# STM32G563 register map
File version: 2.0.0
CPU: CM33 r0p4, little endian, MPU, FPU, 4 interrupt priority bits
Registers are 32-bit, read-write, reset 0x0 unless marked. A register's access mark holds for its fields unless they carry their own. Offsets are from the block's base; [hi:lo] are bit positions; {n}, {i} and the like mark numbered series; 'fields as' and 'values as' point back to an identical list.

## TIM16 — TIM16 address block description
Base 0x40014400
Same registers: TIM16_S 0x50014400
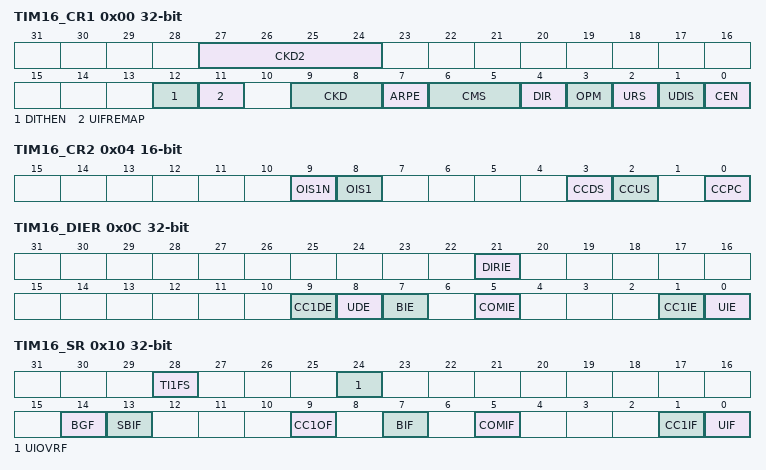
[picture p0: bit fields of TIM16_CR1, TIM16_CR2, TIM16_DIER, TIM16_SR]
0x00 TIM16_CR1 — TIM16 control register 1
  [27:24] CKD2 — Clock division 2
    0=No Division; 1=tless thansub>DTS2less than/sub> = 4*tless thansub>DTSless than/sub>; 2=tless thansub>DTS2less than/sub> = 16*tless thansub>DTSless than/sub>; 3=tless thansub>DTS2less than/sub> = 64*tless thansub>DTSless than/sub>; 4=tless thansub>DTS2less than/sub> = 256*tless thansub>DTSless than/sub>; 5=tless thansub>DTS2less than/sub> = 1024*tless thansub>DTSless than/sub>; 6=tless thansub>DTS2less than/sub> = 4096*tless thansub>DTSless than/sub>; 7=tless thansub>DTS2less than/sub> = 16384*tless thansub>DTSless than/sub>; 8=tless thansub>DTS2less than/sub> = 65536*tless thansub>DTSless than/sub>; 9=tless thansub>DTS2less than/sub> = 262144*tless thansub>DTSless than/sub>
  [12] DITHEN — Dithering enable
    0=Dithering disabled; 1=Dithering enabled
  [11] UIFREMAP — UIF status bit remapping
    0=No remapping. UIF status bit is not copied to TIMx_CNT register bit 31.; 1=Remapping enabled. UIF status bit is copied to TIMx_CNT register bit 31.
  [9:8] CKD — Clock division
    0=tless thansub>DTSless than/sub> = tless thansub>tim_ker_ckless than/sub>; 1=tless thansub>DTSless than/sub> = 2*tless thansub>tim_ker_ckless than/sub>; 2=tless thansub>DTSless than/sub> = 4*tless thansub>tim_ker_ckless than/sub>; 3=tless thansub>DTSless than/sub> = 8*tless thansub>tim_ker_ckless than/sub>
  [7] ARPE — Auto-reload preload enable
    0=TIMx_ARR register is not buffered; 1=TIMx_ARR register is buffered
  [6:5] CMS — Center-aligned mode selection
    0=Edge-aligned mode. The counter counts up or down depending on the direction bit (DIR).; 1=Center-aligned mode 1. The counter counts up and down alternatively. Output compare interrupt flags of channels configured in output (CCxS = 00 in TIMx_CCMRx register) are set only when the counter is counting down.; 2=Center-aligned mode 2. The counter counts up and down alternatively. Output compare interrupt flags of channels configured in output (CCxS = 00 in TIMx_CCMRx register) are set only when the counter is counting up.; 3=Center-aligned mode 3. The counter counts up and down alternatively. Output compare interrupt flags of channels configured in output (CCxS = 00 in TIMx_CCMRx register) are set both when the counter is counting up or down.
  [4] DIR — Direction
    0=Counter used as upcounter; 1=Counter used as downcounter
  [3] OPM — One pulse mode
    0=Counter is not stopped at update event; 1=Counter stops counting at the next update event (clearing the bit CEN)
  [2] URS — Update request source
    0=Any of the following events generate an update interrupt or DMA request if enabled. These events can be:; 1=nly counter overflow/underflow generates an update interrupt or DMA request if enabled
  [1] UDIS — Update disable
    0=UEV enabled. The Update (UEV) event is generated by one of the following events:; 1=UEV disabled. The Update event is not generated, shadow registers keep their value (ARR, PSC, CCRx). However the counter and the prescaler are reinitialized if the UG bit is set or if a hardware reset is received from the slave mode controller.
  [0] CEN — Counter enable
    0=Counter disabled; 1=Counter enabled
0x04 TIM16_CR2 16-bit — TIM16 control register 2
  [9] OIS1N — Output Idle state 1 (tim_oc1n output)
    0=tim_oc1n = 0 after a dead-time when MOE = 0; 1=tim_oc1n = 1 after a dead-time when MOE = 0
  [8] OIS1 — Output Idle state 1 (tim_oc1 output)
    0=tim_oc1 = 0 after a dead-time when MOE = 0; 1=tim_oc1 = 1 after a dead-time when MOE = 0
  [3] CCDS — Capture/compare DMA selection
    0=CCx DMA request sent when CCx event occurs; 1=CCx DMA requests sent when update event occurs
  [2] CCUS — Capture/compare control update selection
    0=When capture/compare control bits are preloaded (CCPC = 1), they are updated by setting the COMG bit only; 1=When capture/compare control bits are preloaded (CCPC = 1), they are updated by setting the COMG bit or when a rising edge occurs on tim_trgi (if available)
  [0] CCPC — Capture/compare preloaded control
    0=CCxE, CCxNE and OCxM bits are not preloaded; 1=CCxE, CCxNE and OCxM bits are preloaded, after having been written, they are updated only when COM bit is set
0x0C TIM16_DIER — TIM16 DMA/interrupt enable register
  [21] DIRIE — Direction change interrupt enable
    0=Direction change interrupt disabled; 1=Direction change interrupt enabled
  [9] CC1DE — Capture/Compare 1 DMA request enable
    0=CC1 DMA request disabled; 1=CC1 DMA request enabled
  [8] UDE — Update DMA request enable
    0=Update DMA request disabled; 1=Update DMA request enabled
  [7] BIE — Break interrupt enable
    0=Break interrupt disabled; 1=Break interrupt enabled
  [5] COMIE — COM interrupt enable
    0=COM interrupt disabled; 1=COM interrupt enabled
  [1] CC1IE — Capture/Compare 1 interrupt enable
    0=CC1 interrupt disabled; 1=CC1 interrupt enabled
  [0] UIE — Update interrupt enable
    0=Update interrupt disabled; 1=Update interrupt enabled
0x10 TIM16_SR — TIM16 status register
  [28] TI1FS ro — tim_ti1f status
    0=tim_ti1f signal is low; 1=tim_ti1f signal is high
  [24] UIOVRF — Update Interrupt Overrun flag
    0=No Update Interrupt Overrun; 1=Update Interrupt Overrun
  [14] BGF — Break generation flag
    0=No break event occurred; 1=A break event was forced with the BG bit
  [13] SBIF — System break interrupt flag
    0=No break event occurred; 1=An active level has been detected on the system break input. An interrupt is generated if BIE = 1 in the TIMx_DIER register.
  [9] CC1OF — Capture/Compare 1 overcapture flag
    0=No overcapture has been detected; 1=The counter value has been captured in TIMx_CCR1 register while CC1IF flag was already set
  [7] BIF — Break interrupt flag
    0=No break event occurred; 1=An active level has been detected on the break input
  [5] COMIF — COM interrupt flag
    0=No COM event occurred; 1=COM interrupt pending
  [1] CC1IF — Capture/Compare 1 interrupt flag
    0=No compare match / No input capture occurred; 1=A compare match or an input capture occurred
  [0] UIF — Update interrupt flag
    0=No update occurred; 1=Update interrupt pending. This bit is set by hardware when the registers are updated:
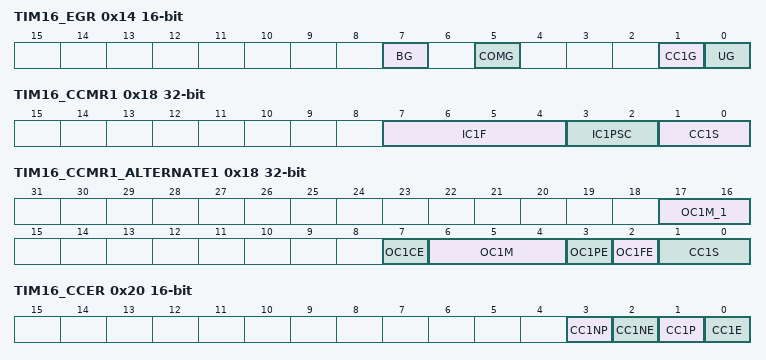
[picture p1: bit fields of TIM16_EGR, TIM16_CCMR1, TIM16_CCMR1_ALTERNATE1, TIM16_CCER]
0x14 TIM16_EGR 16-bit wo — TIM16 event generation register
  [7] BG — Break generation
    0=No action; 1=A break event is generated. MOE bit is cleared and BIF flag is set. Related interrupt or DMA transfer can occur if enabled.
  [5] COMG — Capture/Compare control update generation
    0=No action; 1=When the CCPC bit is set, it is possible to update the CCxE, CCxNE and OCxM bits
  [1] CC1G — Capture/Compare 1 generation
    0=No action; 1=A capture/compare event is generated on channel 1:
  [0] UG — Update generation
    0=No action; 1=Reinitialize the counter and generates an update of the registers. Note that the prescaler counter is cleared too (anyway the prescaler ratio is not affected).
0x18 TIM16_CCMR1 — TIM16 capture/compare mode register 1
  [7:4] IC1F — Input capture 1 filter
    0=No filter, sampling is done at fless thansub>DTSless than/sub>; 1=fless thansub>SAMPLINGless than/sub> = fless thansub>tim_ker_ckless than/sub>, N = 2; 2=fless thansub>SAMPLINGless than/sub> = fless thansub>tim_ker_ckless than/sub>, N = 4; 3=fless thansub>SAMPLINGless than/sub> = fless thansub>tim_ker_ckless than/sub>, N = 8; 4=fless thansub>SAMPLINGless than/sub> = fless thansub>DTSless than/sub>/2, N =; 5=fless thansub>SAMPLINGless than/sub> = fless thansub>DTSless than/sub>/2, N = 8; 6=fless thansub>SAMPLINGless than/sub> = fless thansub>DTSless than/sub>/4, N = 6; 7=fless thansub>SAMPLINGless than/sub> = fless thansub>DTSless than/sub>/4, N = 8; 8=fless thansub>SAMPLINGless than/sub> = fless thansub>DTSless than/sub>/8, N = 6; 9=fless thansub>SAMPLINGless than/sub> = fless thansub>DTSless than/sub>/8, N = 8; 10=fless thansub>SAMPLINGless than/sub> = fless thansub>DTSless than/sub>/16, N = 5; 11=fless thansub>SAMPLINGless than/sub> = fless thansub>DTSless than/sub>/16, N = 6; 12=fless thansub>SAMPLINGless than/sub> = fless thansub>DTSless than/sub>/16, N = 8; 13=fless thansub>SAMPLINGless than/sub> = fless thansub>DTSless than/sub>/32, N = 5; 14=fless thansub>SAMPLINGless than/sub> = fless thansub>DTSless than/sub>/32, N = 6; 15=fless thansub>SAMPLINGless than/sub> = fless thansub>DTSless than/sub>/32, N = 8
  [3:2] IC1PSC — Input capture 1 prescaler
    0=no prescaler, capture is done each time an edge is detected on the capture input; 1=capture is done once every 2 events; 2=capture is done once every 4 events; 3=capture is done once every 8 events
  [1:0] CC1S — Capture/Compare 1 selection
    0=CC1 channel is configured as output; 1=CC1 channel is configured as input, tim_ic1 is mapped on tim_ti1
0x18 TIM16_CCMR1_ALTERNATE1 (alternate view of TIM16_CCMR1) — TIM16 capture/compare mode register 1
  [17:16] OC1M_1 — OC1M[4:3]
  [7] OC1CE — Output Compare 1 clear enable
    0=tim_oc1ref is not affected by the tim_ocref_clr input; 1=tim_oc1ref is cleared as soon as a High level is detected on tim_ocref_clr input
  [6:4] OC1M — OC1M[2:0]: Output Compare 1 mode
    0=Frozen - The comparison between the output compare register TIMx_CCR1 and the counter TIMx_CNT has no effect on the outputs. This mode can be used when the timer serves as a software timebase. When the frozen mode is enabled during timer operation, the output keeps the state (active or inactive) it had before entering the frozen state.; 1=Set channel 1 to active level on match. tim_oc1ref signal is forced high when the counter TIMx_CNT matches the capture/compare register 1 (TIMx_CCR1).; 2=Set channel 1 to inactive level on match. tim_oc1ref signal is forced low when the counter TIMx_CNT matches the capture/compare register 1 (TIMx_CCR1).; 3=Toggle - tim_oc1ref toggles when TIMx_CNT = TIMx_CCR1; 4=Force inactive level - tim_oc1ref is forced low; 5=Force active level - tim_oc1ref is forced high; 6=PWM mode 1 - Channel 1 is active as long as TIMx_CNTless thanTIMx_CCR1 else inactive; 7=PWM mode 2 - Channel 1 is inactive as long as TIMx_CNTless thanTIMx_CCR1 else active
  [3] OC1PE — Output Compare 1 preload enable
    0=Preload register on TIMx_CCR1 disabled. TIMx_CCR1 can be written at anytime, the new value is taken in account immediately.; 1=Preload register on TIMx_CCR1 enabled. Read/Write operations access the preload register. TIMx_CCR1 preload value is loaded in the active register at each update event.
  [2] OC1FE — Output Compare 1 fast enable
    0=CC1 behaves normally depending on counter and CCR1 values even when the trigger is ON. The minimum delay to activate CC1 output when an edge occurs on the trigger input is 5 clock cycles.; 1=An active edge on the trigger input acts like a compare match on CC1 output. Then, tim_ocx is set to the compare level independently of the result of the comparison. Delay to sample the trigger input and to activate CC1 output is reduced to 3 clock cycles. OC1FE acts only if the channel is configured in PWM1 or PWM2 mode.
  [1:0] CC1S — Capture/Compare 1 selection
    values as TIM16_CCMR1.CC1S
0x20 TIM16_CCER 16-bit — TIM16 capture/compare enable register
  [3] CC1NP — Capture/Compare 1 complementary output polarity
    0=tim_oc1n active high; 1=tim_oc1n active low
  [2] CC1NE — Capture/Compare 1 complementary output enable
    0=Off - tim_oc1n is not active. tim_oc1n level is then function of MOE, OSSI, OSSR, OIS1, OIS1N and CC1E bits.; 1=On - tim_oc1n signal is output on the corresponding output pin depending on MOE, OSSI, OSSR, OIS1, OIS1N and CC1E bits
  [1] CC1P — Capture/Compare 1 output polarity
    0=OC1 active high (output mode) / Edge sensitivity selection (input mode, see below); 1=OC1 active low (output mode) / Edge sensitivity selection (input mode, see below)
  [0] CC1E — Capture/Compare 1 output enable
    0=Capture mode disabled / OC1 is not active (see below); 1=Capture mode enabled / OC1 signal is output on the corresponding output pin
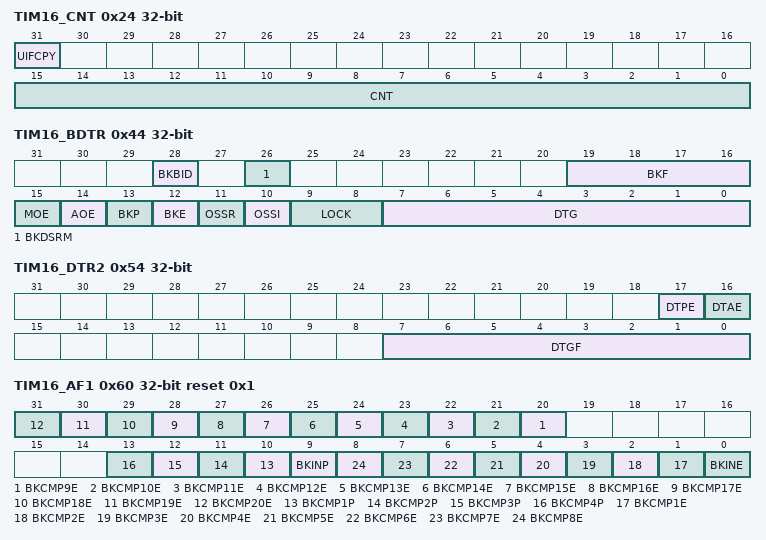
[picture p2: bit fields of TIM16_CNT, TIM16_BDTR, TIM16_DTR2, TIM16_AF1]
0x24 TIM16_CNT — TIM16 counter
  [31] UIFCPY ro — UIF Copy
  [15:0] CNT — Counter value
0x28 TIM16_PSC 16-bit — TIM16 prescaler
  [15:0] PSC — Prescaler value
0x2C TIM16_ARR reset 0xFFFF — TIM16 auto-reautoreload register
  [19:0] ARR — Auto-reload value
0x30 TIM16_RCR 16-bit — TIM16 repetition counter register
  [7:0] REP — Repetition counter reload value
0x34 TIM16_CCR1 — TIM16 capture/compare register 1
  [19:0] CCR1 — Capture/Compare 1 value
0x44 TIM16_BDTR — TIM16 break and dead-time register
  [28] BKBID — Break Bidirectional
    0=Break input tim_brk in input mode; 1=Break input tim_brk in bidirectional mode
  [26] BKDSRM — Break Disarm
    0=Break input tim_brk is armed; 1=Break input tim_brk is disarmed
  [19:16] BKF — Break filter
    0=No filter, tim_brk acts asynchronously; 1=fless thansub>SAMPLINGless than/sub> = fless thansub>tim_ker_ckless than/sub>, N = 2; 2=fless thansub>SAMPLINGless than/sub> = fless thansub>tim_ker_ckless than/sub>, N = 4; 3=fless thansub>SAMPLINGless than/sub> = fless thansub>tim_ker_ckless than/sub>, N = 8; 4=fless thansub>SAMPLINGless than/sub> = fless thansub>DTSless than/sub>/2, N = 6; 5=fless thansub>SAMPLINGless than/sub> = fless thansub>DTSless than/sub>/2, N = 8; 6=fless thansub>SAMPLINGless than/sub> = fless thansub>DTSless than/sub>/4, N = 6; 7=fless thansub>SAMPLINGless than/sub> = fless thansub>DTSless than/sub>/4, N = 8; 8=fless thansub>SAMPLINGless than/sub> = fless thansub>DTSless than/sub>/8, N = 6; 9=fless thansub>SAMPLINGless than/sub> = fless thansub>DTSless than/sub>/8, N = 8; 10=fless thansub>SAMPLINGless than/sub> = fless thansub>DTSless than/sub>/16, N = 5; 11=fless thansub>SAMPLINGless than/sub> = fless thansub>DTSless than/sub>/16, N = 6; 12=fless thansub>SAMPLINGless than/sub> = fless thansub>DTSless than/sub>/16, N = 8; 13=fless thansub>SAMPLINGless than/sub> = fless thansub>DTSless than/sub>/32, N = 5; 14=fless thansub>SAMPLINGless than/sub> = fless thansub>DTSless than/sub>/32, N = 6; 15=fless thansub>SAMPLINGless than/sub> = fless thansub>DTSless than/sub>/32, N = 8
  [15] MOE — Main output enable
    0=tim_oc1 and tim_oc1n outputs are disabled or forced to idle state depending on the OSSI bit; 1=tim_oc1 and tim_oc1n outputs are enabled if their respective enable bits are set (CC1E, CC1NE in TIMx_CCER register)
  [14] AOE — Automatic output enable
    0=MOE can be set only by software; 1=MOE can be set by software or automatically at the next update event (if the tim_brk input is not active)
  [13] BKP — Break polarity
    0=Break input tim_brk is active low; 1=Break input tim_brk is active high
  [12] BKE — Break enable
    0=Break inputs (tim_brk and tim_sys_brk event) disabled
  [11] OSSR — Off-state selection for Run mode
    0=When inactive, tim_oc1/tim_oc1n outputs are disabled (the timer releases the output control which is taken over by the GPIO, which forces a Hi-Z state); 1=When inactive, tim_oc1/tim_oc1n outputs are enabled with their inactive level as soon as CC1E = 1 or CC1NE = 1 (the output is still controlled by the timer)
  [10] OSSI — Off-state selection for Idle mode
    0=When inactive, tim_oc1/tim_oc1n outputs are disabled (tim_oc1/tim_oc1n enable output signal = 0); 1=When inactive, tim_oc1/tim_oc1n outputs are forced first with their idle level as soon as CC1E = 1 or CC1NE = 1. tim_oc1/tim_oc1n enable output signal = 1)
  [9:8] LOCK — Lock configuration
    0=LOCK OFF - No bit is write protected; 1=LOCK Level 1 = DTG bits in TIMx_BDTR register, OISx and OISxN bits in TIMx_CR2 register and BKBID/BKE/BKP/AOE bits in TIMx_BDTR register can no longer be written; 2=LOCK Level 2 = LOCK Level 1 + CC Polarity bits (CCxP/CCxNP bits in TIMx_CCER register, as long as the related channel is configured in output through the CCxS bits) as well as OSSR and OSSI bits can no longer be written; 3=LOCK Level 3 = LOCK Level 2 + CC Control bits (OCxM and OCxPE bits in TIMx_CCMRx registers, as long as the related channel is configured in output through the CCxS bits) can no longer be written
  [7:0] DTG — Dead-time generator setup
0x54 TIM16_DTR2 — TIM16 timer deadtime register 2
  [17] DTPE — Deadtime preload enable
    0=Deadtime value is not preloaded; 1=Deadtime value preload is enabled
  [16] DTAE — Deadtime asymmetric enable
    0=Deadtime on rising and falling edges are identical, and defined with DTG[7:0] register; 1=Deadtime on rising edge is defined with DTG[7:0] register and deadtime on falling edge is defined with DTGF[7:0] bits
  [7:0] DTGF — Dead-time falling edge generator setup
0x5C TIM16_TISEL — TIM16 input selection register
  [3:0] TI1SEL — selects tim_ti1_in[15:0] input
    0=TIMx_CH1 input (tim_ti1_in0); 1=tim_ti1_in1; 15=tim_ti1_in15
0x60 TIM16_AF1 reset 0x1 — TIM16 alternate function register 1
  [n+11] BKCMP{n}E (n=9..20) — tim_brk_cmp{n} enable
    0=tim_brk_cmp{n} input disabled; 1=tim_brk_cmp{n} input enabled
  [n+9] BKCMP{n}P (n=1..4) — tim_brk_cmp{n} input polarity
    0=tim_brk_cmp{n} input is active high; 1=tim_brk_cmp{n} input is active low
  [9] BKINP — TIMx_BKIN input polarity
    0=TIMx_BKIN input is active high; 1=TIMx_BKIN input is active low
  [n] BKCMP{n}E (n=1..8) — tim_brk_cmp{n} enable
    values as BKCMP9E
  [0] BKINE — TIMx_BKIN input enable
    0=TIMx_BKIN input disabled; 1=TIMx_BKIN input enabled
0x64 TIM16_AF2 — TIM16 alternate function register 2
  [19:16] OCRSEL — tim_ocref_clr source selection
    0=tim_ocref_clr0; 1=tim_ocref_clr1; 15=tim_ocref_clr15
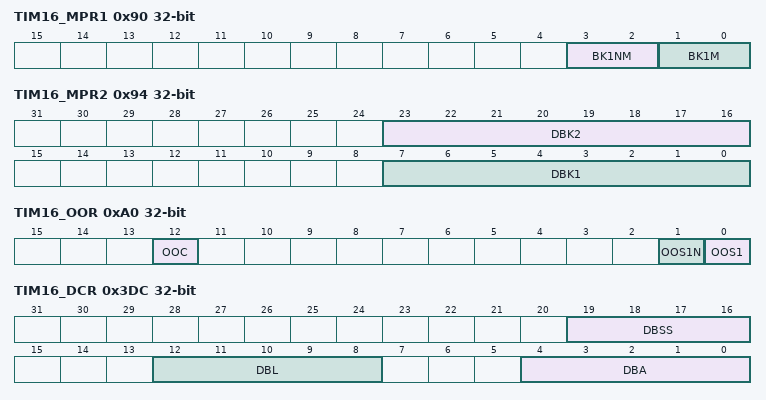
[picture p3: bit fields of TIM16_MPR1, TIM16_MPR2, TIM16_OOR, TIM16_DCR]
0x90 TIM16_MPR1 — TIM16 multilevel protection register 1
  [3:2] BK1NM — Break mode for tim_oc1n output
    0=Immediate break; 1=Delayed 1 break; 2=Delayed 2 break
  [1:0] BK1M — Break mode for tim_oc1 output
    0=Immediate break; 1=Delayed 1 break; 2=Delayed 2 break
0x94 TIM16_MPR2 — TIM16 multilevel protection register 2
  [23:16] DBK2 — Delayed 2 Break duration
  [7:0] DBK1 — Delayed 1 Break duration
0xA0 TIM16_OOR — TIM16 output override register
  [12] OOC — Output override control
    0=tim_ocx and tim_ocxn outputs are in the default idle state; 1=tim_ocx and tim_ocxn outputs are forced in an idle state defined with OOSx/OOSxN bits
  [1] OOS1N — Output override state for output tim_oc1n
    0=tim_oc1n = 0; 1=tim_oc1n = 1
  [0] OOS1 — Output override state for output tim_oc1
    0=tim_oc1 = 0; 1=tim_oc1 = 1
0x3DC TIM16_DCR — TIM16 DMA control register
  [19:16] DBSS — DMA burst source selection
    1=Update; 2=CC1
  [12:8] DBL — DMA burst length
    0=1 transfer,; 1=2 transfers,; 2=3 transfers,; 17=18 transfers
  [4:0] DBA — DMA base address
    0=TIMx_CR1,; 1=TIMx_CR2,; 2=TIMx_SMCR,
0x3E0 TIM16_DMAR — TIM16/TIM17 DMA address for full transfer
  [31:0] DMAB — DMA register for burst accesses

## TIM17 — TIM17 address block description
Base 0x40014800
Same registers: TIM17_S 0x50014800
Registers as TIM16 (with TIM16 read as TIM17); these are added or differ:
0x3E0 TIM17_DMAR — TIM16/TIM17 DMA address for full transfer
  [31:0] DMAB — DMA register for burst accesses
